# ATtiny1634 device description
Architecture: AVR8; Family: tinyAVR
Registers are 8-bit, access not given, no defined reset value unless marked. A register's access mark holds for its fields unless they carry their own. Offsets are from the block's base; [hi:lo] are bit positions; {n}, {i} and the like mark numbered series.

## CPU — CPU Registers
Instances: CPU 0x00
{0x34+i} GPIOR{i} (i=0..2) — General Purpose I/O Register {i}
0x4F CCP — Configuration Change Protection
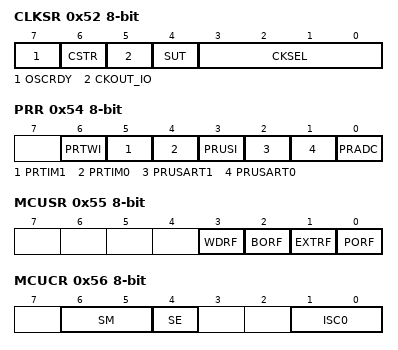
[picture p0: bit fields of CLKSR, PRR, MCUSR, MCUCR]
0x52 CLKSR — Clock Setting Register
  [7] OSCRDY — Oscillator Ready
  [6] CSTR — Clock Switch Trigger
  [5] CKOUT_IO — Clock Output (active low)
  [4] SUT — Start-up Time
  [3:0] CKSEL — Clock Select Bits
0x53 CLKPR — Clock Prescale Register
  [3:0] CLKPS — Clock Prescaler Select Bits
    0=1; 1=2; 2=4; 3=8; 4=16; 5=32; 6=64; 7=128; 8=256
0x54 PRR — Power Reduction Register
  [6] PRTWI — Power Reduction TWI
  [5] PRTIM1 — Power Reduction Timer/Counter1
  [4] PRTIM0 — Power Reduction Timer/Counter0
  [3] PRUSI — Power Reduction USI
  [2] PRUSART1 — Power Reduction USART1
  [1] PRUSART0 — Power Reduction USART0
  [0] PRADC — Power Reduction ADC
0x55 MCUSR — MCU Status Register
  [3] WDRF — Watchdog Reset Flag
  [2] BORF — Brown-out Reset Flag
  [1] EXTRF — External Reset Flag
  [0] PORF — Power-on reset flag
0x56 MCUCR — MCU Control Register
  [6:5] SM — Sleep Mode Select Bits
    0=IDLE; 1=ADC (ADC Noise Reduction (If Available)); 2=PDOWN (Power Down); 3=STDBY (Standby)
  [4] SE — Sleep Enable
  [1:0] ISC0 — Interrupt Sense Control 0 bits
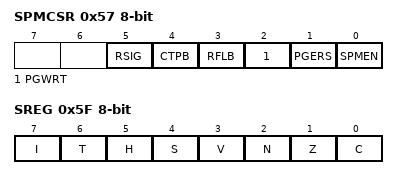
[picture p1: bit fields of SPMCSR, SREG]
0x57 SPMCSR — Store Program Memory Control and Status Register
  [5] RSIG — Read Device Signature Imprint Table
  [4] CTPB — Clear Temporary Page Buffer
  [3] RFLB — Read Fuse and Lock Bits
  [2] PGWRT — Page Write
  [1] PGERS — Page Erase
  [0] SPMEN — Store program Memory Enable
0x5D SP 16-bit bits used 10:0 — Stack Pointer
0x5F SREG — Status Register
  [7] I — Global Interrupt Enable
  [6] T — Bit Copy Storage
  [5] H — Half Carry Flag
  [4] S — Sign Bit
  [3] V — Two's Complement Overflow Flag
  [2] N — Negative Flag
  [1] Z — Zero Flag
  [0] C — Carry Flag
0x63 OSCCAL0 — Oscillator Calibration Value
0x64 OSCTCAL0A
0x65 OSCTCAL0B
0x66 OSCCAL1 bits used 1:0

## USI — Universal Serial Interface
Instances: USI 0x00
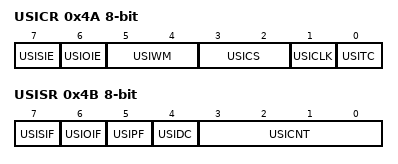
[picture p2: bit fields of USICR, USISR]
0x4A USICR — USI Control Register
  [7] USISIE — Start Condition Interrupt Enable
  [6] USIOIE — Counter Overflow Interrupt Enable
  [5:4] USIWM — USI Wire Mode Bits
    0=NORMAL_OPERATION; 1=THREE_WIRE_MODE; 2=TWO_WIRE_MODE; 3=TWO_WIRE_MODE_HELD_LOW
  [3:2] USICS — USI Clock Source Select Bits
  [1] USICLK — Clock Strobe
  [0] USITC — Toggle Clock Port Pin
0x4B USISR — USI Status Register
  [7] USISIF — Start Condition Interrupt Flag
  [6] USIOIF — Counter Overflow Interrupt Flag
  [5] USIPF — Stop Condition Flag
  [4] USIDC — Data Output Collision
  [3:0] USICNT — USI Counter Value Bits
0x4C USIDR — USI Data Register
0x4D USIBR — USI Buffer Register

## USART0 — USART
Instances: USART0 0x00
0x40 UDR0 — USART I/O Data Register
0x41 UBRR0 16-bit bits used 11:0 — USART Baud Rate Register Bytes
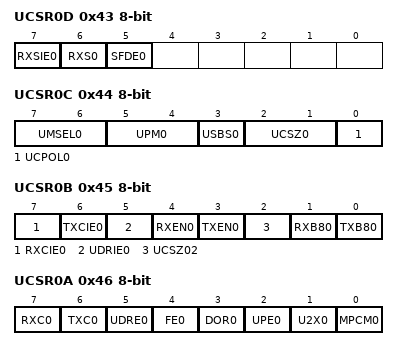
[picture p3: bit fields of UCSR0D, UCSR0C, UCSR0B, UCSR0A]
0x43 UCSR0D — USART Control and Status Register D
  [7] RXSIE0 — USART RX Start Interrupt Enable
  [6] RXS0 — USART RX Start Flag
  [5] SFDE0 — USART RX Start Frame Detection Enable
0x44 UCSR0C — USART Control and Status Register C
  [7:6] UMSEL0 — USART Mode Select
    0=ASYNCHRONOUS_USART; 1=SYNCHRONOUS_USART; 3=MASTER_SPI
  [5:4] UPM0 — Parity Mode Bits
    0=DISABLED; 2=ENABLED_EVEN_PARITY; 3=ENABLED_ODD_PARITY
  [3] USBS0 — Stop Bit Select
    0=1_BIT; 1=2_BIT
  [2:1] UCSZ0 — Character Size
  [0] UCPOL0 — Clock Polarity
0x45 UCSR0B — USART Control and Status Register B
  [7] RXCIE0 — RX Complete Interrupt Enable
  [6] TXCIE0 — TX Complete Interrupt Enable
  [5] UDRIE0 — USART Data register Empty Interrupt Enable
  [4] RXEN0 — Receiver Enable
  [3] TXEN0 — Transmitter Enable
  [2] UCSZ02 — Character Size
  [1] RXB80 — Receive Data Bit 8
  [0] TXB80 — Transmit Data Bit 8
0x46 UCSR0A — USART Control and Status Register A
  [7] RXC0 ro — USART Receive Complete
  [6] TXC0 — USART Transmit Complete
  [5] UDRE0 ro — USART Data Register Empty
  [4] FE0 ro — Framing Error
  [3] DOR0 ro — Data overRun
  [2] UPE0 ro — Parity Error
  [1] U2X0 — Double the USART transmission speed
  [0] MPCM0 — Multi-processor Communication Mode

## USART1 — USART
Instances: USART1 0x00
0x73 UDR1 — USART I/O Data Register
0x74 UBRR1 16-bit bits used 11:0 — USART Baud Rate Register Bytes
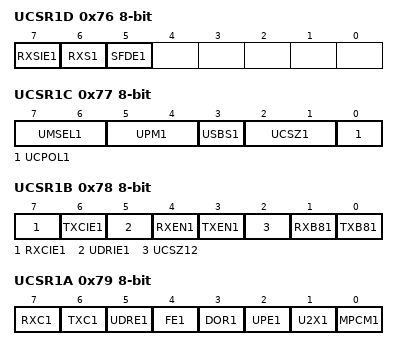
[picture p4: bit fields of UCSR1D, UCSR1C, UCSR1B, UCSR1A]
0x76 UCSR1D — USART Control and Status Register D
  [7] RXSIE1 — USART RX Start Interrupt Enable
  [6] RXS1 — USART RX Start Flag
  [5] SFDE1 — USART RX Start Frame Detection Enable
0x77 UCSR1C — USART Control and Status Register C
  [7:6] UMSEL1 — USART Mode Select
    0=ASYNCHRONOUS_USART; 1=SYNCHRONOUS_USART; 3=MASTER_SPI
  [5:4] UPM1 — Parity Mode Bits
    0=DISABLED; 2=ENABLED_EVEN_PARITY; 3=ENABLED_ODD_PARITY
  [3] USBS1 — Stop Bit Select
    0=1_BIT; 1=2_BIT
  [2:1] UCSZ1 — Character Size
  [0] UCPOL1 — Clock Polarity
0x78 UCSR1B — USART Control and Status Register B
  [7] RXCIE1 — RX Complete Interrupt Enable
  [6] TXCIE1 — TX Complete Interrupt Enable
  [5] UDRIE1 — USART Data register Empty Interrupt Enable
  [4] RXEN1 — Receiver Enable
  [3] TXEN1 — Transmitter Enable
  [2] UCSZ12 — Character Size
  [1] RXB81 — Receive Data Bit 8
  [0] TXB81 — Transmit Data Bit 8
0x79 UCSR1A — USART Control and Status Register A
  [7] RXC1 — USART Receive Complete
  [6] TXC1 — USART Transmit Complete
  [5] UDRE1 — USART Data Register Empty
  [4] FE1 — Framing Error
  [3] DOR1 — Data overRun
  [2] UPE1 — Parity Error
  [1] U2X1 — Double the USART transmission speed
  [0] MPCM1 — Multi-processor Communication Mode

## WDT — Watchdog Timer
Instances: WDT 0x00
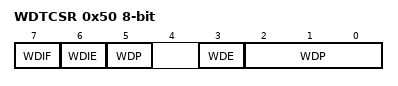
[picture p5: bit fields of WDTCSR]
0x50 WDTCSR — Watchdog Timer Control and Status Register
  [7] WDIF — Watchdog Timer Interrupt Flag
  [6] WDIE — Watchdog Timer Interrupt Enable
  [3] WDE — Watch Dog Enable
  [5,2:0] WDP — Watchdog Timer Prescaler Bits
    0=OSCILLATOR_CYCLES_512_16_MS; 1=OSCILLATOR_CYCLES_1K_32_MS; 2=OSCILLATOR_CYCLES_2K_64_MS; 3=OSCILLATOR_CYCLES_4K_0_125_S; 4=OSCILLATOR_CYCLES_8K_0_25_S; 5=OSCILLATOR_CYCLES_16K_0_5_S; 6=OSCILLATOR_CYCLES_32K_1_0_S; 7=OSCILLATOR_CYCLES_64K_2_0_S; 8=OSCILLATOR_CYCLES_128K_4_0_S; 9=OSCILLATOR_CYCLES_256K_8_0_S
